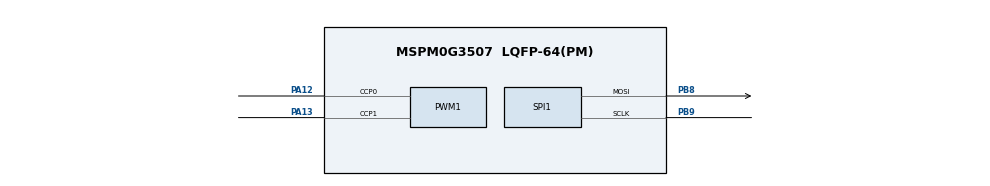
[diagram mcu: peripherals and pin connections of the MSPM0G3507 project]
//@cliArgs --device "MSPM0G350X" --package "LQFP-64(PM)" --part "Default"
//@v2CliArgs --device "MSPM0G3507" --package "LQFP-64(PM)"
// @cliArgs --board /ti/boards/LP_MSPM0G3507 --rtos nortos

/**
 * Import the modules used in this configuration.
 */
const GPIO   = scripting.addModule("/ti/driverlib/GPIO", {}, false);
const GPIO1  = GPIO.addInstance();
const PWM    = scripting.addModule("/ti/driverlib/PWM", {}, false);
const PWM1   = PWM.addInstance();
const SPI    = scripting.addModule("/ti/driverlib/SPI", {}, false);
const SPI1   = SPI.addInstance();
const SYSCTL = scripting.addModule("/ti/driverlib/SYSCTL");

/**
 * Write custom configuration values to the imported modules.
 */
GPIO1.$name                          = "DC_MOTOR";
GPIO1.associatedPins.create(8);
GPIO1.associatedPins[0].$name        = "AIN1";
GPIO1.associatedPins[0].assignedPort = "PORTA";
GPIO1.associatedPins[0].assignedPin  = "8";
GPIO1.associatedPins[1].$name        = "AIN2";
GPIO1.associatedPins[1].assignedPort = "PORTA";
GPIO1.associatedPins[1].assignedPin  = "15";
GPIO1.associatedPins[2].$name        = "STBY";
GPIO1.associatedPins[2].assignedPort = "PORTB";
GPIO1.associatedPins[2].assignedPin  = "24";
GPIO1.associatedPins[3].$name        = "BIN1";
GPIO1.associatedPins[3].assignedPort = "PORTB";
GPIO1.associatedPins[3].assignedPin  = "13";
GPIO1.associatedPins[4].$name        = "BIN2";
GPIO1.associatedPins[4].assignedPort = "PORTB";
GPIO1.associatedPins[4].assignedPin  = "12";
GPIO1.associatedPins[5].$name        = "OLED_RES";
GPIO1.associatedPins[5].assignedPort = "PORTB";
GPIO1.associatedPins[5].assignedPin  = "3";
GPIO1.associatedPins[6].$name        = "OLED_DC";
GPIO1.associatedPins[6].assignedPort = "PORTB";
GPIO1.associatedPins[6].assignedPin  = "2";
GPIO1.associatedPins[7].$name        = "OLED_CS";
GPIO1.associatedPins[7].assignedPort = "PORTA";
GPIO1.associatedPins[7].assignedPin  = "27";

const Board = scripting.addModule("/ti/driverlib/Board", {}, false);

PWM1.$name                              = "PWMA";
PWM1.timerCount                         = 3200;
PWM1.PWM_CHANNEL_0.$name                = "ti_driverlib_pwm_PWMTimerCC0";
PWM1.PWM_CHANNEL_0.ccValue              = 3200;
PWM1.ccp0PinConfig.$name                = "ti_driverlib_gpio_GPIOPinGeneric0";
PWM1.ccp0PinConfig.direction            = scripting.forceWrite("OUTPUT");
PWM1.ccp0PinConfig.hideOutputInversion  = scripting.forceWrite(false);
PWM1.ccp0PinConfig.onlyInternalResistor = scripting.forceWrite(false);
PWM1.ccp0PinConfig.passedPeripheralType = scripting.forceWrite("Digital");
PWM1.ccp0PinConfig.enableConfig         = true;
PWM1.peripheral.$assign                 = "TIMG0";
PWM1.peripheral.ccp0Pin.$assign         = "PA12";
PWM1.peripheral.ccp1Pin.$assign         = "PA13";
PWM1.PWM_CHANNEL_1.$name                = "ti_driverlib_pwm_PWMTimerCC1";
PWM1.ccp1PinConfig.$name                = "ti_driverlib_gpio_GPIOPinGeneric1";
PWM1.ccp1PinConfig.enableConfig         = true;

SPI1.$name                         = "OLED_SPI";
SPI1.targetBitRate                 = 8000000;
SPI1.peripheral.$assign            = "SPI1";
SPI1.peripheral.sclkPin.$assign    = "PB9";
SPI1.peripheral.mosiPin.$assign    = "PB8";

SYSCTL.forceDefaultClkConfig = true;

/**
 * Pinmux solution for unlocked pins/peripherals.
 */
GPIO1.associatedPins[0].pin.$suggestSolution = "PA8";
GPIO1.associatedPins[1].pin.$suggestSolution = "PA15";
GPIO1.associatedPins[2].pin.$suggestSolution = "PB24";
GPIO1.associatedPins[3].pin.$suggestSolution = "PB13";
GPIO1.associatedPins[4].pin.$suggestSolution = "PB12";
GPIO1.associatedPins[5].pin.$suggestSolution = "PB3";
GPIO1.associatedPins[6].pin.$suggestSolution = "PB2";
GPIO1.associatedPins[7].pin.$suggestSolution = "PA27";
Board.peripheral.$suggestSolution            = "DEBUGSS";
Board.peripheral.swclkPin.$suggestSolution   = "PA20";
Board.peripheral.swdioPin.$suggestSolution   = "PA19";
SYSCTL.peripheral.$suggestSolution           = "SYSCTL";
